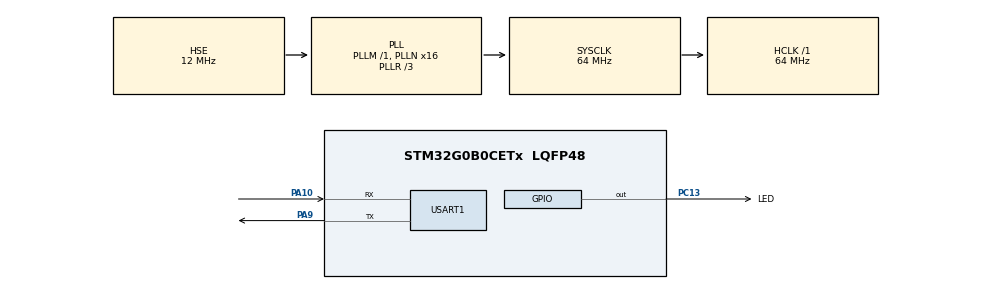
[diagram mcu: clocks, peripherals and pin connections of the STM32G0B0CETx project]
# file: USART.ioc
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Mcu.Family=STM32G0
Mcu.Name=STM32G0B0CETx
Mcu.Package=LQFP48
PA10.Mode=Asynchronous
PA10.Signal=USART1_RX
PA13.Mode=Serial_Wire
PA13.Signal=SYS_SWDIO
PA14-BOOT0.Mode=Serial_Wire
PA14-BOOT0.Signal=SYS_SWCLK
PA9.Mode=Asynchronous
PA9.Signal=USART1_TX
PC13.GPIO_Label=LED
PC13.Signal=GPIO_Output
PF0-OSC_IN\ (PF0).Mode=HSE-External-Oscillator
PF0-OSC_IN\ (PF0).Signal=RCC_OSC_IN
PF1-OSC_OUT\ (PF1).Mode=HSE-External-Oscillator
PF1-OSC_OUT\ (PF1).Signal=RCC_OSC_OUT
ProjectManager.HeapSize=0x200
ProjectManager.StackSize=0x400
ProjectManager.TargetToolchain=MDK-ARM V5.32
RCC.ADCFreq_Value=64000000
RCC.AHBFreq_Value=64000000
RCC.CortexFreq_Value=64000000
RCC.EXTERNAL_CLOCK_VALUE=48000
RCC.FLatency=FLASH_LATENCY_2
RCC.HCLKFreq_Value=64000000
RCC.HSE_VALUE=12000000
RCC.HSI_VALUE=16000000
RCC.LSE_VALUE=32768
RCC.PLLN=16
RCC.PLLR=RCC_PLLR_DIV3
RCC.PLLSourceVirtual=RCC_PLLSOURCE_HSE
RCC.SYSCLKFreq_VALUE=64000000
RCC.SYSCLKSource=RCC_SYSCLKSOURCE_PLLCLK
RCC.USBFreq_Value=96000000
RCC.VCOOutputFreq_Value=192000000
USART1.VirtualMode-Asynchronous=VM_ASYNC
VP_SYS_VS_DBSignals.Mode=DisableDeadBatterySignals
board=custom

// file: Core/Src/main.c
/* USER CODE BEGIN Header */
/**
  ******************************************************************************
  * @file           : main.c
  * @brief          : Main program body
  ******************************************************************************
  * @attention
  *
  * <h2><center>&copy; Copyright (c) 2021 STMicroelectronics.
  * All rights reserved.</center></h2>
  *
  * This software component is licensed by ST under BSD 3-Clause license,
  * the "License"; You may not use this file except in compliance with the
  * License. You may obtain a copy of the License at:
  *                        opensource.org/licenses/BSD-3-Clause
  *
  ******************************************************************************
  */
/* USER CODE END Header */
#include "main.h"
#include "usart.h"
#include "gpio.h"

/* USER CODE BEGIN Includes */
#include <stdio.h>

/* USER CODE END Includes */

/* USER CODE BEGIN PV */
uint8_t rx_buf;
uint8_t tx_buf[] = "X Pulse STM32G0B0CET6 usart test...\r\n";

/* USER CODE END PV */

void SystemClock_Config(void);

/* USER CODE BEGIN 0 */
void HAL_UART_RxCpltCallback(UART_HandleTypeDef *huart)
{
		if(huart->Instance == USART1) {
				HAL_UART_Transmit(&huart1, &rx_buf, sizeof(rx_buf), 1000);
				HAL_UART_Receive_IT(&huart1, &rx_buf, sizeof(rx_buf));
		}
}

int fputc(int ch, FILE *f)
{
    HAL_UART_Transmit(&huart1, (uint8_t *)&ch, 1, 1000);

    return ch;
}

/* USER CODE END 0 */

int main(void)
{

  /* MCU Configuration--------------------------------------------------------*/

  /* Reset of all peripherals, Initializes the Flash interface and the Systick. */
  HAL_Init();

  /* Configure the system clock */
  SystemClock_Config();

  /* Initialize all configured peripherals */
  MX_GPIO_Init();
  MX_USART1_UART_Init();
  /* USER CODE BEGIN 2 */

	/* 开启 USART 1 中断 */
	HAL_UART_Receive_IT(&huart1, &rx_buf, sizeof(rx_buf));

  /* USER CODE END 2 */

  /* Infinite loop */
  /* USER CODE BEGIN WHILE */
  while (1)
  {
		HAL_UART_Transmit(&huart1, tx_buf, sizeof(tx_buf), 1000);
		HAL_Delay(500);
		printf("X Pulse STM32G0B0CET6 printf test...\r\n");
		HAL_Delay(500);
		HAL_GPIO_TogglePin(GPIOC, GPIO_PIN_13);
    /* USER CODE END WHILE */

  }
}

void SystemClock_Config(void)
{
  RCC_OscInitTypeDef RCC_OscInitStruct = {0};
  RCC_ClkInitTypeDef RCC_ClkInitStruct = {0};

  /** Configure the main internal regulator output voltage
  */
  HAL_PWREx_ControlVoltageScaling(PWR_REGULATOR_VOLTAGE_SCALE1);

  /** Initializes the RCC Oscillators according to the specified parameters
  * in the RCC_OscInitTypeDef structure.
  */
  RCC_OscInitStruct.OscillatorType = RCC_OSCILLATORTYPE_HSE;
  RCC_OscInitStruct.HSEState = RCC_HSE_ON;
  RCC_OscInitStruct.PLL.PLLState = RCC_PLL_ON;
  RCC_OscInitStruct.PLL.PLLSource = RCC_PLLSOURCE_HSE;
  RCC_OscInitStruct.PLL.PLLM = RCC_PLLM_DIV1;
  RCC_OscInitStruct.PLL.PLLN = 16;
  RCC_OscInitStruct.PLL.PLLP = RCC_PLLP_DIV2;
  RCC_OscInitStruct.PLL.PLLQ = RCC_PLLQ_DIV2;
  RCC_OscInitStruct.PLL.PLLR = RCC_PLLR_DIV3;
  if (HAL_RCC_OscConfig(&RCC_OscInitStruct) != HAL_OK)
  {
    Error_Handler();
  }

  /** Initializes the CPU, AHB and APB buses clocks
  */
  RCC_ClkInitStruct.ClockType = RCC_CLOCKTYPE_HCLK|RCC_CLOCKTYPE_SYSCLK
                              |RCC_CLOCKTYPE_PCLK1;
  RCC_ClkInitStruct.SYSCLKSource = RCC_SYSCLKSOURCE_PLLCLK;
  RCC_ClkInitStruct.AHBCLKDivider = RCC_SYSCLK_DIV1;
  RCC_ClkInitStruct.APB1CLKDivider = RCC_HCLK_DIV1;

  if (HAL_RCC_ClockConfig(&RCC_ClkInitStruct, FLASH_LATENCY_2) != HAL_OK)
  {
    Error_Handler();
  }
}

void Error_Handler(void)
{
  __disable_irq();
  while (1)
  {
  }
}
